# f2838x_cm_nvic_regs register map
Vendor: Texas Instruments
Peripheral module from a debugger description file (folder C2000).
Address unit: 16 bits
Registers are 32-bit, read-write, no defined reset value unless marked. A register's access mark holds for its fields unless they carry their own. Offsets are as the file gives them; lines under a group give offsets from that group; [hi:lo] are bit positions; {n}, {i} and the like mark numbered series; 'fields as' and 'values as' point back to an identical list; <NAME> marks a mode.

## NVIC — NVIC Registers
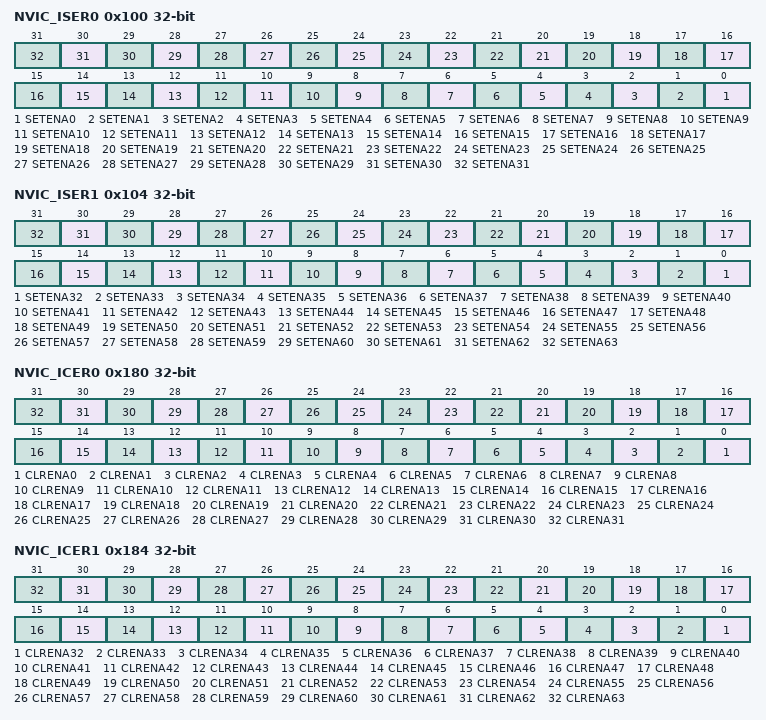
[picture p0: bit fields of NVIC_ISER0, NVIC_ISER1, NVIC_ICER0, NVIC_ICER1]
0x100 NVIC_ISER0 — NVIC Interrupt Set Enable Register 0
  [n] SETENA{n} (n=0..31) — Set INTR{n} Enable
0x104 NVIC_ISER1 — NVIC Interrupt Set Enable Register 1
  [n-32] SETENA{n} (n=32..63) — Set INTR{n} Enable
0x180 NVIC_ICER0 — NVIC Interrupt Clear Enable Register 0
  [n] CLRENA{n} (n=0..31) — Clear INTR{n} Enable
0x184 NVIC_ICER1 — NVIC Interrupt Clear Enable Register 1
  [n-32] CLRENA{n} (n=32..63) — Clear INTR{n} Enable
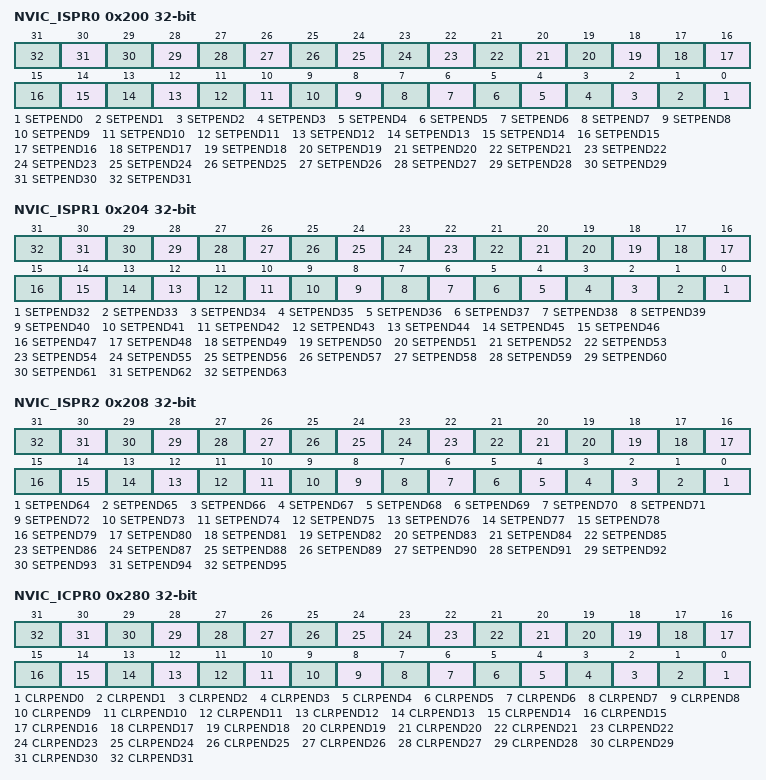
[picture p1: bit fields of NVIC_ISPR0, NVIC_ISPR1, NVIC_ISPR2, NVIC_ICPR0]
0x200 NVIC_ISPR0 — NVIC Interrupt Set Pending Register 0
  [n] SETPEND{n} (n=0..31) — Set INTR{n} Pending
0x204 NVIC_ISPR1 — NVIC Interrupt Set Pending Register 1
  [n-32] SETPEND{n} (n=32..63) — Set INTR{n} Pending
0x208 NVIC_ISPR2 — NVIC Interrupt Set Pending Register 2
  [n-64] SETPEND{n} (n=64..95) — Set INTR{n} Pending
0x280 NVIC_ICPR0 — NVIC Interrupt Clear Pending Register 0
  [n] CLRPEND{n} (n=0..31) — Clear INTR{n} Pending
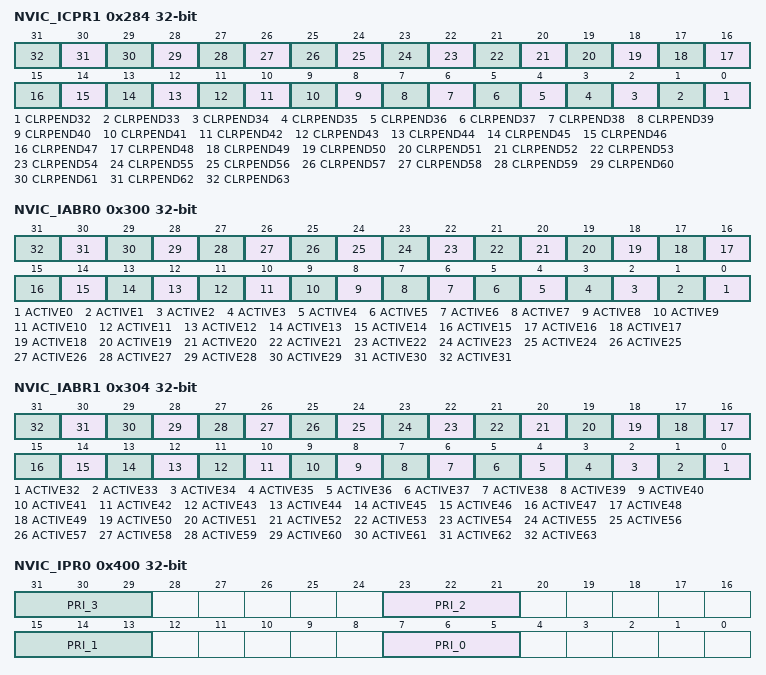
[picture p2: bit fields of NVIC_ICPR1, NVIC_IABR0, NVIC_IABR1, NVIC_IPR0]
0x284 NVIC_ICPR1 — NVIC Interrupt Clear Pending Register 1
  [n-32] CLRPEND{n} (n=32..63) — Clear INTR{n} Pending
0x300 NVIC_IABR0 ro — NVIC Interrupt Active Bit Register 0
  [n] ACTIVE{n} (n=0..31) — INTR{n} Active
0x304 NVIC_IABR1 ro — NVIC Interrupt Active Bit Register 1
  [n-32] ACTIVE{n} (n=32..63) — INTR{n} Active
0x400 NVIC_IPR0 — NVIC Interrupt Priority Register 0
  [8n+7:8n+5] PRI_{n} (n=0..3) — Priority, byte offset {n}
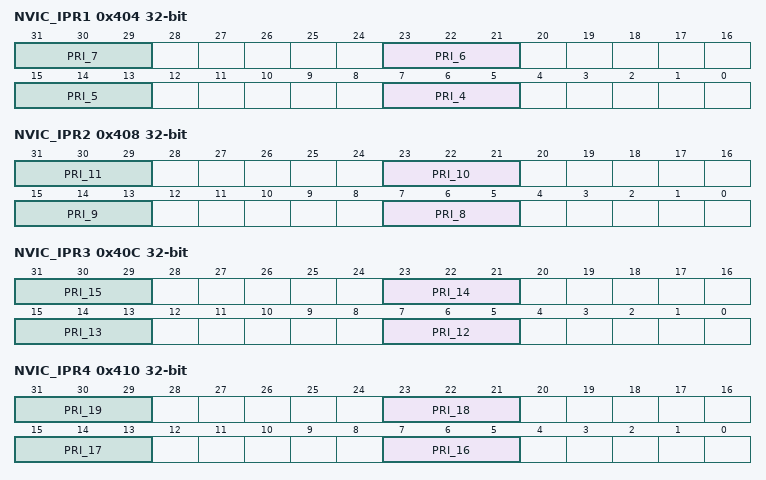
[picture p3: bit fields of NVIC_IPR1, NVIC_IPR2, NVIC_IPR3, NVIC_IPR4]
0x404 NVIC_IPR1 — NVIC Interrupt Priority Register 1
  [8n-25:8n-27] PRI_{n} (n=4..7) — Priority, byte offset {n}
0x408 NVIC_IPR2 — NVIC Interrupt Priority Register 2
  [8n-57:8n-59] PRI_{n} (n=8..11) — Priority, byte offset {n}
0x40C NVIC_IPR3 — NVIC Interrupt Priority Register 3
  [8n-89:8n-91] PRI_{n} (n=12..15) — Priority, byte offset {n}
0x410 NVIC_IPR4 — NVIC Interrupt Priority Register 4
  [8n-121:8n-123] PRI_{n} (n=16..19) — Priority, byte offset {n}
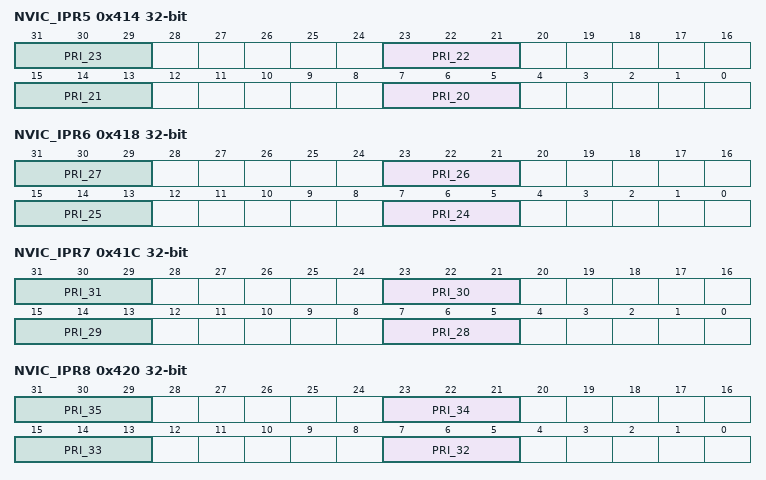
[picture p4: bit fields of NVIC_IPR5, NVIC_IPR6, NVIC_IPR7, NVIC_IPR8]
0x414 NVIC_IPR5 — NVIC Interrupt Priority Register 5
  [8n-153:8n-155] PRI_{n} (n=20..23) — Priority, byte offset {n}
0x418 NVIC_IPR6 — NVIC Interrupt Priority Register 6
  [8n-185:8n-187] PRI_{n} (n=24..27) — Priority, byte offset {n}
0x41C NVIC_IPR7 — NVIC Interrupt Priority Register 7
  [8n-217:8n-219] PRI_{n} (n=28..31) — Priority, byte offset {n}
0x420 NVIC_IPR8 — NVIC Interrupt Priority Register 8
  [8n-249:8n-251] PRI_{n} (n=32..35) — Priority, byte offset {n}
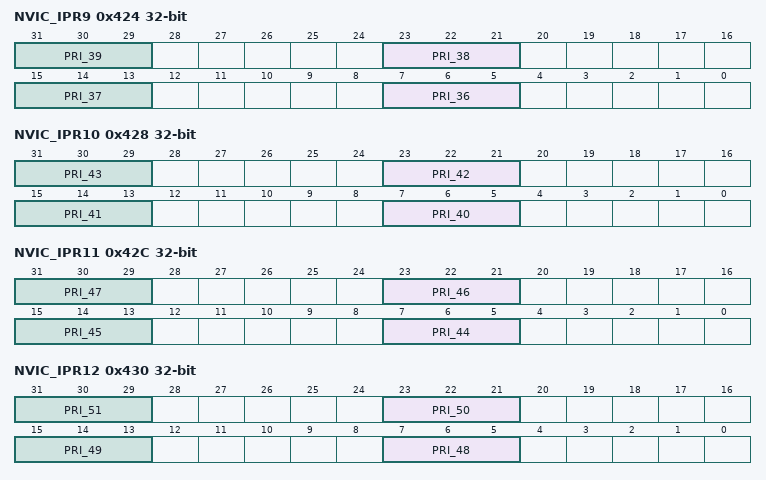
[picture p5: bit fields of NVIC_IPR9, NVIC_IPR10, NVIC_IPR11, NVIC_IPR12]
0x424 NVIC_IPR9 — NVIC Interrupt Priority Register 9
  [8n-281:8n-283] PRI_{n} (n=36..39) — Priority, byte offset {n}
0x428 NVIC_IPR10 — NVIC Interrupt Priority Register 10
  [8n-313:8n-315] PRI_{n} (n=40..43) — Priority, byte offset {n}
0x42C NVIC_IPR11 — NVIC Interrupt Priority Register 11
  [8n-345:8n-347] PRI_{n} (n=44..47) — Priority, byte offset {n}
0x430 NVIC_IPR12 — NVIC Interrupt Priority Register 12
  [8n-377:8n-379] PRI_{n} (n=48..51) — Priority, byte offset {n}
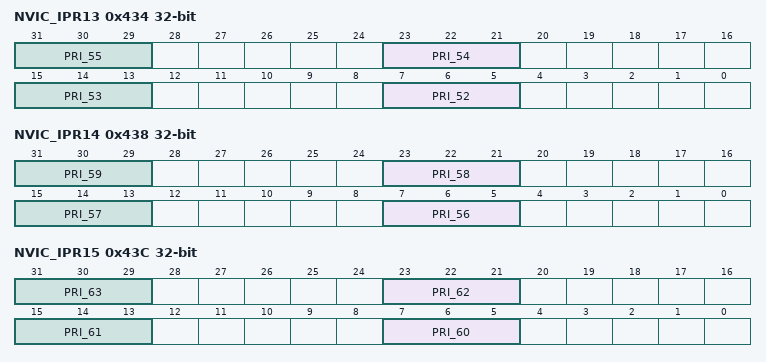
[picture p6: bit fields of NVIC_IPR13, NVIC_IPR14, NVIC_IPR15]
0x434 NVIC_IPR13 — NVIC Interrupt Priority Register 13
  [8n-409:8n-411] PRI_{n} (n=52..55) — Priority, byte offset {n}
0x438 NVIC_IPR14 — NVIC Interrupt Priority Register 14
  [8n-441:8n-443] PRI_{n} (n=56..59) — Priority, byte offset {n}
0x43C NVIC_IPR15 — NVIC Interrupt Priority Register 15
  [8n-473:8n-475] PRI_{n} (n=60..63) — Priority, byte offset {n}
0xF00 STIR — Software Trigger Interrupt Register
  [8:0] INTID — Software Trigger Interrupt Register.
